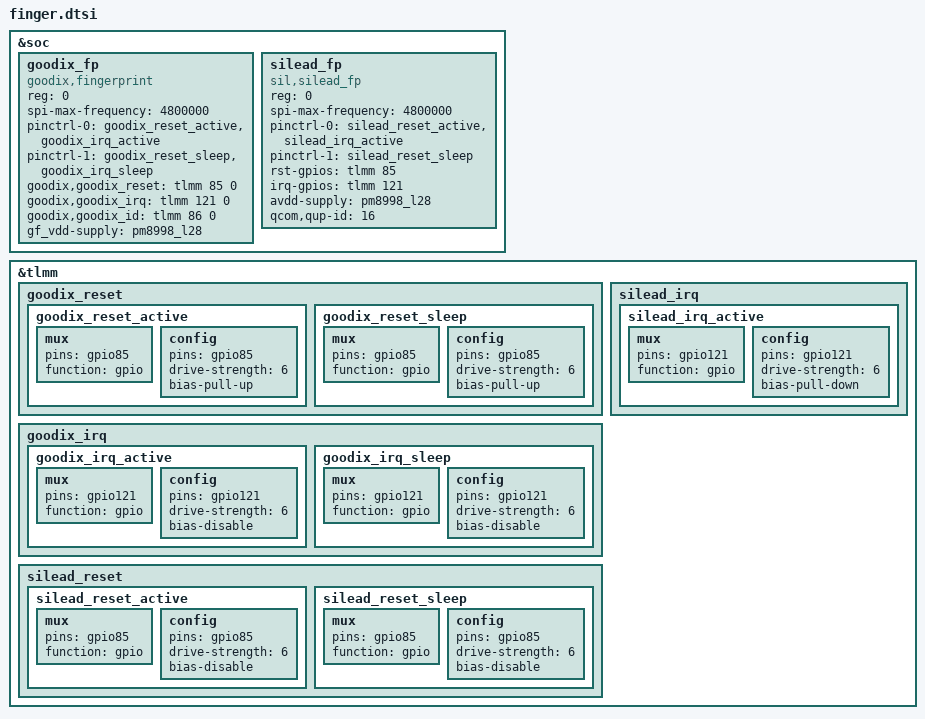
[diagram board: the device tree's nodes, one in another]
/*
 * Copyright (c) 2015-2016, The Linux Foundation. All rights reserved.
 *
 * This program is free software; you can redistribute it and/or modify
 * it under the terms of the GNU General Public License version 2 and
 * only version 2 as published by the Free Software Foundation.
 *
 * This program is distributed in the hope that it will be useful,
 * but WITHOUT ANY WARRANTY; without even the implied warranty of
 * MERCHANTABILITY or FITNESS FOR A PARTICULAR PURPOSE.  See the
 * GNU General Public License for more details.
 */
&soc {
        /* used for fingerprint device as platform device added by nubia start*/
	goodix_fp{
	        status = "ok";
	        reg = <0>;
	        compatible = "goodix,fingerprint";
	        spi-max-frequency = <4800000>;
	        pinctrl-names = "gf_fp_active", "gf_fp_suspend";
	        pinctrl-0 = <&goodix_reset_active &goodix_irq_active>;
	        pinctrl-1 = <&goodix_reset_sleep &goodix_irq_sleep>;
	        goodix,goodix_reset = <&tlmm 85 0>;
	        goodix,goodix_irq = <&tlmm 121 0>;
			goodix,goodix_id = <&tlmm 86 0>;
			gf_vdd-supply = <&pm8998_l28>;
	};
	/* used for fingerprint device as platform device added by nubia end*/
};

/*****finger pinctrl start *****/
&tlmm {
		goodix_reset {
			goodix_reset_active: goodix_reset_active {
				mux {
					pins = "gpio85";
					function = "gpio";
				};

				config {
					pins = "gpio85";
					drive-strength = <6>;
					bias-pull-up;
				};
			};

			goodix_reset_sleep: goodix_reset_sleep {
				mux {
					pins = "gpio85";
					function = "gpio";
				};

				config {
					pins = "gpio85";
					drive-strength = <6>;
					bias-pull-up;
				};
			};
		};

		goodix_irq {
			goodix_irq_active: goodix_irq_active {
				mux {
					pins = "gpio121";
					function = "gpio";
				};

				config {
					pins = "gpio121";
					drive-strength = <6>;
					bias-disable;
				};
			};

			goodix_irq_sleep: goodix_irq_sleep {
				mux {
					pins = "gpio121";
					function = "gpio";
				};

				config {
					pins = "gpio121";
					drive-strength = <6>;
					bias-disable;
				};
			};
		};
};

&soc {
        /* used for fingerprint device as platform device added by nubia start*/
	silead_fp{
	        status = "ok";
	        reg = <0>;
	        compatible = "sil,silead_fp";
	        spi-max-frequency = <4800000>;
	        pinctrl-names = "spi_default", "spi_sleep";
	        pinctrl-0 = <&silead_reset_active &silead_irq_active>;
	        pinctrl-1 = <&silead_reset_sleep>;
	        rst-gpios = <&tlmm 85 0>;
	        irq-gpios = <&tlmm 121 0>;
		avdd-supply = <&pm8998_l28>;
		/*vddio-supply = <&pm8998_l15>;*/
		qcom,qup-id = <16>;
	};
	/* used for fingerprint device as platform device added by nubia end*/
};

/*****finger pinctrl start *****/
&tlmm {
		silead_reset {
			silead_reset_active: silead_reset_active {
				mux {
					pins = "gpio85";
					function = "gpio";
				};

				config {
					pins = "gpio85";
					drive-strength = <6>;
					bias-disable;
				};
			};

			silead_reset_sleep: silead_reset_sleep {
				mux {
					pins = "gpio85";
					function = "gpio";
				};

				config {
					pins = "gpio85";
					drive-strength = <6>;
					bias-disable;
				};
			};
		};

		silead_irq {
			silead_irq_active: silead_irq_active {
				mux {
					pins = "gpio121";
					function = "gpio";
				};

				config {
					pins = "gpio121";
					drive-strength = <6>;
					bias-pull-down;
				};
			};

		};
};
